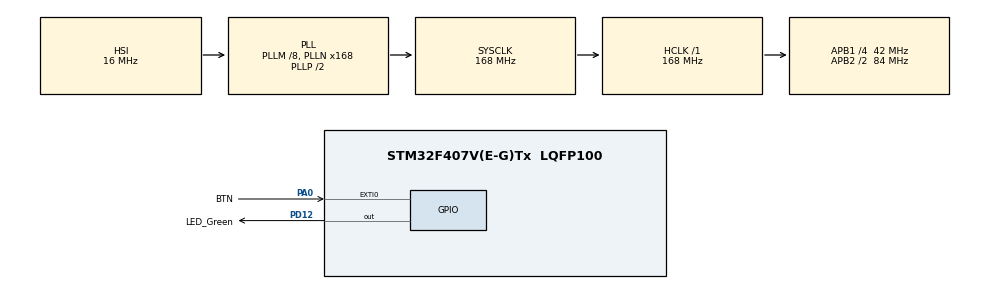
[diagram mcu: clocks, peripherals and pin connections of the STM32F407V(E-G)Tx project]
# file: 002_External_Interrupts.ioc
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Mcu.Family=STM32F4
Mcu.Name=STM32F407V(E-G)Tx
Mcu.Package=LQFP100
NVIC.EXTI0_IRQn=true\:0\:0\:false\:false\:true\:true\:true\:true
NVIC.PriorityGroup=NVIC_PRIORITYGROUP_4
PA0-WKUP.GPIO_Label=BTN
PA0-WKUP.GPIO_PuPd=GPIO_PULLDOWN
PA0-WKUP.Signal=GPXTI0
PA13.Mode=Trace_Asynchronous_SW
PA13.Signal=SYS_JTMS-SWDIO
PA14.Mode=Trace_Asynchronous_SW
PA14.Signal=SYS_JTCK-SWCLK
PB3.Mode=Trace_Asynchronous_SW
PB3.Signal=SYS_JTDO-SWO
PD12.GPIO_Label=LED_Green
PD12.Signal=GPIO_Output
PH0-OSC_IN.Mode=HSE-External-Oscillator
PH0-OSC_IN.Signal=RCC_OSC_IN
PH1-OSC_OUT.Mode=HSE-External-Oscillator
PH1-OSC_OUT.Signal=RCC_OSC_OUT
ProjectManager.HeapSize=0x200
ProjectManager.StackSize=0x400
ProjectManager.TargetToolchain=STM32CubeIDE
RCC.48MHZClocksFreq_Value=84000000
RCC.AHBFreq_Value=168000000
RCC.APB1CLKDivider=RCC_HCLK_DIV4
RCC.APB1Freq_Value=42000000
RCC.APB1TimFreq_Value=84000000
RCC.APB2CLKDivider=RCC_HCLK_DIV2
RCC.APB2Freq_Value=84000000
RCC.APB2TimFreq_Value=168000000
RCC.CortexFreq_Value=168000000
RCC.HCLKFreq_Value=168000000
RCC.HSE_VALUE=8000000
RCC.HSI_VALUE=16000000
RCC.LSE_VALUE=32768
RCC.PLLM=8
RCC.PLLN=168
RCC.SYSCLKFreq_VALUE=168000000
RCC.SYSCLKSource=RCC_SYSCLKSOURCE_PLLCLK
RCC.VCOOutputFreq_Value=336000000
board=custom

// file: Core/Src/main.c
/* USER CODE BEGIN Header */
/**
  ******************************************************************************
  * @file           : main.c
  * @brief          : Main program body
  ******************************************************************************
  * @attention
  *
  * Copyright (c) 2025 STMicroelectronics.
  * All rights reserved.
  *
  * This software is licensed under terms that can be found in the LICENSE file
  * in the root directory of this software component.
  * If no LICENSE file comes with this software, it is provided AS-IS.
  *
  ******************************************************************************
  */
/* USER CODE END Header */
#include "main.h"

/* USER CODE BEGIN Includes */

#include "stdio.h"

/* USER CODE END Includes */

/* USER CODE BEGIN PV */

volatile uint8_t btn_press = 0;

const uint16_t blink_delays[] = {
  1000,
  500,
  200,
  50
};

uint8_t blink_index = 0;
const uint8_t max_blink_index = sizeof(blink_delays) / sizeof(blink_delays[0]) - 1;

/* USER CODE END PV */

void SystemClock_Config(void);
static void MX_GPIO_Init(void);

/* USER CODE BEGIN 0 */

// Fungsi Untuk Debugging printf ke ITM
int _write(int file, char *ptr, int len) {
  for (int DataIdx = 0; DataIdx < len; DataIdx++) {
    ITM_SendChar(*ptr++);
  }
  return len;
}

/* USER CODE END 0 */

int main(void)
{

  /* MCU Configuration--------------------------------------------------------*/

  /* Reset of all peripherals, Initializes the Flash interface and the Systick. */
  HAL_Init();

  /* Configure the system clock */
  SystemClock_Config();

  /* Initialize all configured peripherals */
  MX_GPIO_Init();
  /* USER CODE BEGIN 2 */

  printf("System Started. Current Delay: %d ms\n", blink_delays[blink_index]);

  /* USER CODE END 2 */

  /* Infinite loop */
  /* USER CODE BEGIN WHILE */

  uint32_t now = 0;
  uint32_t last_blink_time = 0;
  uint32_t last_debug_time = 0;

  uint32_t loop_cnt = 0;

  // ReSharper disable once CppDFAEndlessLoop
  while (1)
  {
    now = HAL_GetTick();

    if ((now - last_blink_time) >= blink_delays[blink_index]) {
      HAL_GPIO_TogglePin(LED_Green_GPIO_Port, LED_Green_Pin);
      last_blink_time = now;
    }

    if (btn_press) {
      btn_press = 0;

      blink_index++;
      if (blink_index > max_blink_index) {
        blink_index = 0;
      }

      printf("Button pressed! Now Delay: %d ms\n", blink_delays[blink_index]);

    }

    if ((now - last_debug_time) >= 1000) {

      printf("Tick %lu (loop count = %lu)\n", now / 1000, loop_cnt);

      loop_cnt = 0;
      last_debug_time = now;
    }

    loop_cnt++;

    /* USER CODE END WHILE */

  }
}

void SystemClock_Config(void)
{
  RCC_OscInitTypeDef RCC_OscInitStruct = {0};
  RCC_ClkInitTypeDef RCC_ClkInitStruct = {0};

  /** Configure the main internal regulator output voltage
  */
  __HAL_RCC_PWR_CLK_ENABLE();
  __HAL_PWR_VOLTAGESCALING_CONFIG(PWR_REGULATOR_VOLTAGE_SCALE1);

  /** Initializes the RCC Oscillators according to the specified parameters
  * in the RCC_OscInitTypeDef structure.
  */
  RCC_OscInitStruct.OscillatorType = RCC_OSCILLATORTYPE_HSI;
  RCC_OscInitStruct.HSIState = RCC_HSI_ON;
  RCC_OscInitStruct.HSICalibrationValue = RCC_HSICALIBRATION_DEFAULT;
  RCC_OscInitStruct.PLL.PLLState = RCC_PLL_ON;
  RCC_OscInitStruct.PLL.PLLSource = RCC_PLLSOURCE_HSI;
  RCC_OscInitStruct.PLL.PLLM = 8;
  RCC_OscInitStruct.PLL.PLLN = 168;
  RCC_OscInitStruct.PLL.PLLP = RCC_PLLP_DIV2;
  RCC_OscInitStruct.PLL.PLLQ = 4;
  if (HAL_RCC_OscConfig(&RCC_OscInitStruct) != HAL_OK)
  {
    Error_Handler();
  }

  /** Initializes the CPU, AHB and APB buses clocks
  */
  RCC_ClkInitStruct.ClockType = RCC_CLOCKTYPE_HCLK|RCC_CLOCKTYPE_SYSCLK
                              |RCC_CLOCKTYPE_PCLK1|RCC_CLOCKTYPE_PCLK2;
  RCC_ClkInitStruct.SYSCLKSource = RCC_SYSCLKSOURCE_PLLCLK;
  RCC_ClkInitStruct.AHBCLKDivider = RCC_SYSCLK_DIV1;
  RCC_ClkInitStruct.APB1CLKDivider = RCC_HCLK_DIV4;
  RCC_ClkInitStruct.APB2CLKDivider = RCC_HCLK_DIV2;

  if (HAL_RCC_ClockConfig(&RCC_ClkInitStruct, FLASH_LATENCY_5) != HAL_OK)
  {
    Error_Handler();
  }
}

// ReSharper disable once CppDoxygenUnresolvedReference
static void MX_GPIO_Init(void)
{
  GPIO_InitTypeDef GPIO_InitStruct = {0};

  /* GPIO Ports Clock Enable */
  __HAL_RCC_GPIOH_CLK_ENABLE();
  __HAL_RCC_GPIOA_CLK_ENABLE();
  __HAL_RCC_GPIOD_CLK_ENABLE();
  __HAL_RCC_GPIOB_CLK_ENABLE();

  /*Configure GPIO pin Output Level */
  HAL_GPIO_WritePin(LED_Green_GPIO_Port, LED_Green_Pin, GPIO_PIN_RESET);

  /*Configure GPIO pin : BTN_Pin */
  GPIO_InitStruct.Pin = BTN_Pin;
  GPIO_InitStruct.Mode = GPIO_MODE_IT_RISING;
  GPIO_InitStruct.Pull = GPIO_PULLDOWN;
  HAL_GPIO_Init(BTN_GPIO_Port, &GPIO_InitStruct);

  /*Configure GPIO pin : LED_Green_Pin */
  GPIO_InitStruct.Pin = LED_Green_Pin;
  GPIO_InitStruct.Mode = GPIO_MODE_OUTPUT_PP;
  GPIO_InitStruct.Pull = GPIO_NOPULL;
  GPIO_InitStruct.Speed = GPIO_SPEED_FREQ_LOW;
  HAL_GPIO_Init(LED_Green_GPIO_Port, &GPIO_InitStruct);

  /* EXTI interrupt init*/
  HAL_NVIC_SetPriority(EXTI0_IRQn, 0, 0);
  HAL_NVIC_EnableIRQ(EXTI0_IRQn);

}

/* USER CODE BEGIN 4 */

void HAL_GPIO_EXTI_Callback(uint16_t GPIO_Pin) {
  static uint32_t last_interrupt_time = 0;
  const uint32_t current_time = HAL_GetTick();

  if (GPIO_Pin == BTN_Pin) {
    if ((current_time - last_interrupt_time ) > (200)) {
      btn_press = 1;
      last_interrupt_time = current_time;
    }
  }
}

/* USER CODE END 4 */

void Error_Handler(void)
{
  /* USER CODE BEGIN Error_Handler_Debug */
  /* User can add his own implementation to report the HAL error return state */
  __disable_irq();
  // ReSharper disable once CppDFAEndlessLoop
  while (1)
  {
  }
  /* USER CODE END Error_Handler_Debug */
}
